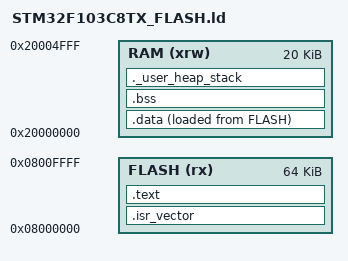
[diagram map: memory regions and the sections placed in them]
/* STM32F103C8T6: 64 KiB Flash, 20 KiB RAM. */
ENTRY(Reset_Handler)

_estack = ORIGIN(RAM) + LENGTH(RAM);
_Min_Heap_Size = 0x200;
_Min_Stack_Size = 0x400;

MEMORY
{
  RAM (xrw)  : ORIGIN = 0x20000000, LENGTH = 20K
  FLASH (rx) : ORIGIN = 0x08000000, LENGTH = 64K
}

SECTIONS
{
  .isr_vector :
  {
    . = ALIGN(4);
    KEEP(*(.isr_vector))
    . = ALIGN(4);
  } >FLASH

  .text :
  {
    . = ALIGN(4);
    *(.text*)
    *(.rodata*)
    . = ALIGN(4);
    _etext = .;
  } >FLASH

  _sidata = LOADADDR(.data);
  .data :
  {
    . = ALIGN(4);
    _sdata = .;
    *(.data*)
    . = ALIGN(4);
    _edata = .;
  } >RAM AT>FLASH

  .bss :
  {
    . = ALIGN(4);
    _sbss = .;
    *(.bss*)
    *(COMMON)
    . = ALIGN(4);
    _ebss = .;
  } >RAM

  ._user_heap_stack :
  {
    . = ALIGN(8);
    PROVIDE(end = .);
    . = . + _Min_Heap_Size;
    . = . + _Min_Stack_Size;
    . = ALIGN(8);
  } >RAM

  /DISCARD/ :
  {
    *libc.a:(*)
    *libm.a:(*)
    *libgcc.a:(*)
  }
}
